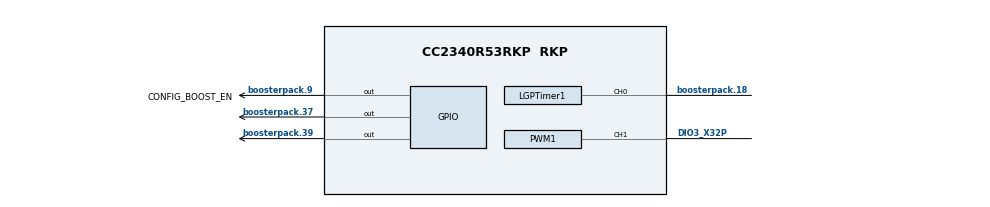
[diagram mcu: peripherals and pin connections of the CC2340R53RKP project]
/**
 * @cliArgs --board "/ti/boards/LP_EM_CC2340R53" --device "CC2340R53RKP" --part "Default" --package "RKP" --rtos "freertos" --product "simplelink_lowpower_f3_sdk@9.12.00.19"
 * @versions {"tool":"1.23.2+4156"}
 */
scripting.excludeFromBuild("ti_ble_config.c");

/**
 * Import the modules used in this configuration.
 */
const FreeRTOS       = scripting.addModule("/freertos/FreeRTOS");
const ble            = scripting.addModule("/ti/ble/ble");
const CCFG           = scripting.addModule("/ti/devices/CCFG");
const rfdesign       = scripting.addModule("/ti/devices/radioconfig/rfdesign");
const Display        = scripting.addModule("/ti/display/Display");
const Display1       = Display.addInstance();
const ADCBuf         = scripting.addModule("/ti/drivers/ADCBuf", {}, false);
const ADCBuf1        = ADCBuf.addInstance();
const AESCCM         = scripting.addModule("/ti/drivers/AESCCM");
const AESCCM1        = AESCCM.addInstance();
const AESCTRDRBG     = scripting.addModule("/ti/drivers/AESCTRDRBG");
const AESCTRDRBG1    = AESCTRDRBG.addInstance();
const AESECB         = scripting.addModule("/ti/drivers/AESECB");
const AESECB1        = AESECB.addInstance();
const BatteryMonitor = scripting.addModule("/ti/drivers/BatteryMonitor");
const ECDH           = scripting.addModule("/ti/drivers/ECDH");
const ECDH1          = ECDH.addInstance();
const GPIO           = scripting.addModule("/ti/drivers/GPIO");
const GPIO2          = GPIO.addInstance();
const GPIO3          = GPIO.addInstance();
const GPIO4          = GPIO.addInstance();
const GPIO5          = GPIO.addInstance();
const LGPTimer       = scripting.addModule("/ti/drivers/LGPTimer", {}, false);
const LGPTimer1      = LGPTimer.addInstance();
const LGPTimer2      = LGPTimer.addInstance();
const NVS            = scripting.addModule("/ti/drivers/NVS");
const NVS1           = NVS.addInstance();
const NVS2           = NVS.addInstance();
const NVS3           = NVS.addInstance();
const PWM            = scripting.addModule("/ti/drivers/PWM", {}, false);
const PWM1           = PWM.addInstance();
const PWM2           = PWM.addInstance();
const Power          = scripting.addModule("/ti/drivers/Power");
const RCL            = scripting.addModule("/ti/drivers/RCL");
const RNG            = scripting.addModule("/ti/drivers/RNG");
const RNG1           = RNG.addInstance();
const SPI            = scripting.addModule("/ti/drivers/SPI", {}, false);
const SPI1           = SPI.addInstance();
const Settings       = scripting.addModule("/ti/posix/freertos/Settings");

/**
 * Write custom configuration values to the imported modules.
 */
FreeRTOS.timerStackSize = 0x00000190;
FreeRTOS.idleStackSize  = 0x00000130;
FreeRTOS.heapSize       = 0x0000AF00;

ble.basicBLE                                        = true;
ble.disDevBySerUuid                                 = true;
ble.numOfAdvSets                                    = 1;
ble.numOfDefAdvSets                                 = 1;
ble.defaultTxPowerValue                             = "8";
ble.maxPDUNum                                       = 50;
ble.maxPDUSize                                      = 255;
ble.disableDisplayModule                            = true;
ble.addressMode                                     = "ADDRMODE_PUBLIC";
ble.deviceName                                      = "Onn Remote";
ble.eccDebugKeys                                    = true;
ble.bondIOCaps                                      = "GAPBOND_IO_CAP_KEYBOARD_DISPLAY";
ble.maxBonds                                        = 1;
ble.radioConfig.codeExportConfig.$name              = "ti_devices_radioconfig_code_export_param0";
ble.adcNoiseConfig.codeExportConfig.$name           = "ti_devices_radioconfig_code_export_param1";
ble.bleCsConfig.codeExportConfig.$name              = "ti_devices_radioconfig_code_export_param2";
ble.connUpdateParamsPeripheral.$name                = "ti_ble_general_ble_conn_update_params0";
ble.connUpdateParamsPeripheral.reqMinConnInt        = 20;
ble.connUpdateParamsPeripheral.reqMaxConnInt        = 20;
ble.connUpdateParamsPeripheral.reqPeripheralLat     = 10;
ble.advSet1.$name                                   = "ti_ble_broadcaster_advertisement_set0";
ble.advSet1.advParam1.$name                         = "ti_ble_broadcaster_advertisement_params0";
ble.advSet1.advParam1.primIntMin                    = 20;
ble.advSet1.advParam1.primIntMax                    = 20;
ble.advSet1.advParam1.txPower                       = "otherTxPower";
ble.advSet1.advData1.$name                          = "ti_ble_broadcaster_advertisement_data0";
ble.advSet1.advData1.GAP_ADTYPE_16BIT_MORE          = true;
ble.advSet1.advData1.GAP_ADTYPE_LOCAL_NAME_COMPLETE = true;
ble.advSet1.advData1.numOfUUIDs16More               = 2;
ble.advSet1.advData1.UUID016More                    = 0x1812;
ble.advSet1.advData1.UUID116More                    = 0x180F;
ble.advSet1.advData1.GAP_ADTYPE_APPEARANCE          = true;
ble.advSet1.advData1.appearanceValue                = 0x180;
ble.advSet1.scanRes1.$name                          = "ti_ble_broadcaster_advertisement_data1";
ble.advSet1.scanRes1.GAP_ADTYPE_POWER_LEVEL         = false;

CCFG.srcClkLF           = "LF RCOSC";
CCFG.bldrEnabled        = true;
CCFG.pinTriggerEnabled  = true;
CCFG.voltageRegulator   = "GLDO";
CCFG.bldrSetting        = "Any bootloader forbidden";
CCFG.ccfgTemplate.$name = "ti_devices_CCFG_CCFGCC23X0Template0";

Display1.$name                                        = "CONFIG_Display_0";
Display1.$hardware                                    = system.deviceData.board.components.XDS110UART;
Display1.enableANSI                                   = true;
Display1.uartBufferSize                               = 128;
Display1.uart.$name                                   = "CONFIG_DISPLAY_UART";
Display1.uart.txPinInstance.$name                     = "CONFIG_PIN_UART_TX";
Display1.uart.rxPinInstance.$name                     = "CONFIG_PIN_UART_RX";
Display1.uart.uart.dmaRxChannel.$assignAllowConflicts = "DMA_CH3";
Display1.uart.uart.txPin.$assignAllowConflicts        = "boosterpack.4";
Display1.uart.uart.rxPin.$assignAllowConflicts        = "boosterpack.3";
scripting.suppress("Resource conflict,@@@.+?@@@ is also in use by @@@.+?@@@", Display1.uart.uart, "dmaRxChannel");

ADCBuf1.$name                                           = "CONFIG_ADCBUF_0";
ADCBuf1.adc.dataDmaChannel.$assignAllowConflicts        = "DMA_CH3";
ADCBuf1.adcChannels[0].$name                            = "CONFIG_ADC_CHANNEL_0";
ADCBuf1.adcChannels[0].adc.adcPin.$assignAllowConflicts = "boosterpack.4";
scripting.suppress("Resource conflict,@@@.+?@@@ is also in use by @@@.+?@@@", ADCBuf1.adc, "dataDmaChannel");

AESCCM1.$name = "CONFIG_AESCCM0";

AESCTRDRBG1.$name = "CONFIG_AESCTRDRBG_0";

AESECB1.$name = "CONFIG_AESECB0";

ECDH1.$name = "CONFIG_ECDH0";

GPIO2.$name                         = "CONFIG_GPIO_LED_GREEN";
GPIO2.mode                          = "Output";
GPIO2.gpioPin.$assignAllowConflicts = "boosterpack.15";

GPIO3.$name           = "CONFIG_GPIO_LED_RED";
GPIO3.mode            = "Output";
GPIO3.gpioPin.$assign = "boosterpack.39";

GPIO4.$name           = "CONFIG_BOOST_EN";
GPIO4.mode            = "Output";
GPIO4.gpioPin.$assign = "boosterpack.9";

GPIO5.$name           = "CONFIG_GPIO_MIC_DTM";
GPIO5.mode            = "Output";
GPIO5.gpioPin.$assign = "boosterpack.37";

LGPTimer1.$name                = "CONFIG_LGPTIMER_0";
LGPTimer1.channel0Connection   = "Pin";
LGPTimer1.timer.ch0Pin.$assign = "boosterpack.18";
scripting.suppress("Connected to hardware,@@@.+?@@@ is connected to LaunchPad SPI Bus Chip Select on the CC2340R53 Development Platform\\. Consider selecting it in \'use hardware\' above\\. @@@.+?@@@", LGPTimer1.timer, "ch0Pin");

LGPTimer2.$name         = "CONFIG_LGPTIMER_1";
LGPTimer2.timer.$assign = "LGPT1";

NVS1.$name                    = "CONFIG_NVSINTERNAL";
NVS1.internalFlash.$name      = "ti_drivers_nvs_NVSLPF30";
NVS1.internalFlash.regionBase = 0x7D000;
NVS1.internalFlash.regionSize = 0x3000;

NVS2.$name                    = "CONFIG_NVSINTERNAL_NEW_IMG";
NVS2.internalFlash.$name      = "ti_drivers_nvs_NVSLPF31";
NVS2.internalFlash.regionType = "Pointer";
NVS2.internalFlash.regionSize = 0x35000;
NVS2.internalFlash.regionBase = 0x3B000;

NVS3.$name                    = "CONFIG_NVSINTERNAL_STORAGE";
NVS3.internalFlash.$name      = "ti_drivers_nvs_NVSLPF32";
NVS3.internalFlash.regionType = "Pointer";
NVS3.internalFlash.regionBase = 0x70000;

PWM1.$name                            = "CONFIG_PWM_0";
PWM1.timerObject.$name                = "CONFIG_LGPTIMER_2";
PWM1.timerObject.channel1Connection   = "Pin";
PWM1.timerObject.timer.ch1Pin.$assign = "DIO3_X32P";
scripting.suppress("Not pinned out,@@@.+?@@@ is not pinned out on the CC2340R53 Development Platform\\.  @@@.+?@@@", PWM1.timerObject.timer, "ch1Pin");

PWM2.$name                          = "CONFIG_PWM_1";
PWM2.timerObject.$name              = "CONFIG_LGPTIMER_3";
PWM2.timerObject.channel1Connection = "Pin";

RNG.rngReturnBehavior = "RNG_RETURN_BEHAVIOR_BLOCKING";

RNG1.$name = "CONFIG_RNG_0";

SPI1.$name                             = "CONFIG_SPI_0";
SPI1.$hardware                         = system.deviceData.board.components.LP_SPI_BUS;
SPI1.minDmaTransferSize                = 32;
SPI1.spi.pociPin.$assignAllowConflicts = "boosterpack.14";
SPI1.spi.picoPin.$assignAllowConflicts = "boosterpack.15";

/**
 * Pinmux solution for unlocked pins/peripherals. This ensures that minor changes to the automatic solver in a future
 * version of the tool will not impact the pinmux you originally saw.  These lines can be completely deleted in order to
 * re-solve from scratch.
 */
Display1.uart.uart.$suggestSolution              = "UART0";
Display1.uart.uart.dmaTxChannel.$suggestSolution = "DMA_CH2";
ADCBuf1.adc.$suggestSolution                     = "ADC";
ADCBuf1.adcChannels[0].adc.$suggestSolution      = "ADC";
LGPTimer1.timer.$suggestSolution                 = "LGPT0";
PWM1.timerObject.timer.$suggestSolution          = "LGPT3";
PWM2.timerObject.timer.$suggestSolution          = "LGPT2";
PWM2.timerObject.timer.ch1Pin.$suggestSolution   = "boosterpack.23";
SPI1.spi.$suggestSolution                        = "SPI0";
SPI1.spi.sclkPin.$suggestSolution                = "boosterpack.7";
SPI1.spi.dmaRxChannel.$suggestSolution           = "DMA_CH1";
SPI1.spi.dmaTxChannel.$suggestSolution           = "DMA_CH0";
